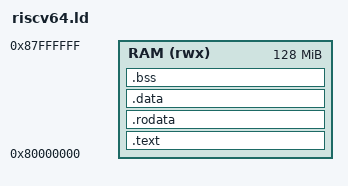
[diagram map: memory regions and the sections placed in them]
ENTRY(_start)

MEMORY {
    RAM (rwx) : ORIGIN = 0x80000000, LENGTH = 128M
}

SECTIONS {
    .text : {
        *(.text.init)
        *(.text*)
    } > RAM

    .rodata : {
        *(.rodata*)
    } > RAM

    .data : {
        *(.data*)
    } > RAM

    .bss : {
        __bss_start = .;
        *(.bss*)
        __bss_end = .;
    } > RAM

    . = ALIGN(16);
    __stack_top = . + 16*1024;
}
